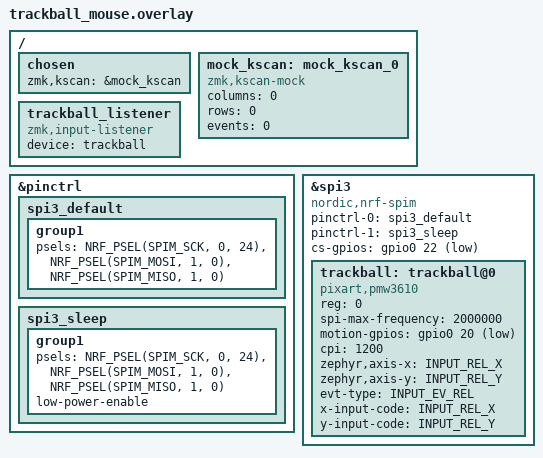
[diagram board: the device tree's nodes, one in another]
/*
 * Pin mapping for nice!nano v2 (Pro Micro footprint):
 * SCK:  P0.24 (Pin D5)
 * SDIO: P1.00 (Pin D6) - Shared MOSI/MISO for 3-wire SPI
 * CS:   P0.22 (Pin D4)
 * IRQ:  P0.20 (Pin D3)
 */

#include <dt-bindings/zmk/pointing.h>
#include <dt-bindings/input/input-event-codes.h>

/ {
    chosen {
        zmk,kscan = &mock_kscan;
    };

    mock_kscan: mock_kscan_0 {
        compatible = "zmk,kscan-mock";
        columns = <0>;
        rows = <0>;
        events = <0>;
    };
};

&pinctrl {
    spi3_default: spi3_default {
        group1 {
            psels = <NRF_PSEL(SPIM_SCK, 0, 24)>,
                    <NRF_PSEL(SPIM_MOSI, 1, 0)>,
                    <NRF_PSEL(SPIM_MISO, 1, 0)>;
        };
    };
    spi3_sleep: spi3_sleep {
        group1 {
            psels = <NRF_PSEL(SPIM_SCK, 0, 24)>,
                    <NRF_PSEL(SPIM_MOSI, 1, 0)>,
                    <NRF_PSEL(SPIM_MISO, 1, 0)>;
            low-power-enable;
        };
    };
};

&spi3 {
    status = "okay";
    compatible = "nordic,nrf-spim";
    pinctrl-0 = <&spi3_default>;
    pinctrl-1 = <&spi3_sleep>;
    pinctrl-names = "default", "sleep";
    cs-gpios = <&gpio0 22 GPIO_ACTIVE_LOW>;

    trackball: trackball@0 {
        status = "okay";
        compatible = "pixart,pmw3610";
        reg = <0>;
        spi-max-frequency = <2000000>;

        motion-gpios = <&gpio0 20 (GPIO_ACTIVE_LOW | GPIO_PULL_UP)>;

        /* CPI settings (default 1200) */
        cpi = <1200>;

        /* Required by Zephyr input bindings */
        zephyr,axis-x = <INPUT_REL_X>;
        zephyr,axis-y = <INPUT_REL_Y>;

        /* ZMK specific properties (kept for compatibility if needed) */
        evt-type = <INPUT_EV_REL>;
        x-input-code = <INPUT_REL_X>;
        y-input-code = <INPUT_REL_Y>;
    };
};

/ {
    trackball_listener: trackball_listener {
        compatible = "zmk,input-listener";
        device = <&trackball>;
    };
};
